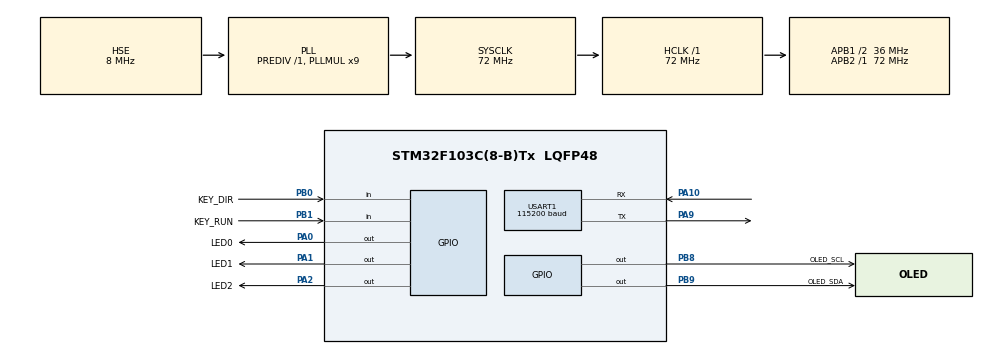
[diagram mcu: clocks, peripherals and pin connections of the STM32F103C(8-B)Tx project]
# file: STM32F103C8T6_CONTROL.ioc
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Mcu.Family=STM32F1
Mcu.Name=STM32F103C(8-B)Tx
Mcu.Package=LQFP48
NVIC.PriorityGroup=NVIC_PRIORITYGROUP_4
PA0.GPIO_Label=LED0
PA0.GPIO_Speed=GPIO_Speed_2MHz
PA0.PinState=GPIO_PIN_RESET
PA0.Signal=GPIO_Output
PA1.GPIO_Label=LED1
PA1.GPIO_Speed=GPIO_Speed_2MHz
PA1.PinState=GPIO_PIN_RESET
PA1.Signal=GPIO_Output
PA2.GPIO_Label=LED2
PA2.GPIO_Speed=GPIO_Speed_2MHz
PA2.PinState=GPIO_PIN_RESET
PA2.Signal=GPIO_Output
PA9.Mode=Asynchronous
PA9.Signal=USART1_TX
PA10.Mode=Asynchronous
PA10.Signal=USART1_RX
PB0.GPIO_Label=KEY_DIR
PB0.GPIO_PuPd=GPIO_PULLUP
PB0.Signal=GPIO_Input
PB1.GPIO_Label=KEY_RUN
PB1.GPIO_PuPd=GPIO_PULLUP
PB1.Signal=GPIO_Input
PB8.GPIO_Label=OLED_SCL
PB8.GPIO_ModeDefaultOutputPP=GPIO_MODE_OUTPUT_OD
PB8.GPIO_PuPd=GPIO_PULLUP
PB8.GPIO_Speed=GPIO_Speed_50MHz
PB8.PinState=GPIO_PIN_SET
PB8.Signal=GPIO_Output
PB9.GPIO_Label=OLED_SDA
PB9.GPIO_ModeDefaultOutputPP=GPIO_MODE_OUTPUT_OD
PB9.GPIO_PuPd=GPIO_PULLUP
PB9.GPIO_Speed=GPIO_Speed_50MHz
PB9.PinState=GPIO_PIN_SET
PB9.Signal=GPIO_Output
ProjectManager.HeapSize=0x200
ProjectManager.StackSize=0x400
ProjectManager.TargetToolchain=STM32CUBEIDE
RCC.AHBFreq_Value=72000000
RCC.APB1CLKDivider=RCC_HCLK_DIV2
RCC.APB1Freq_Value=36000000
RCC.APB1TimFreq_Value=36000000
RCC.APB2Freq_Value=72000000
RCC.APB2TimFreq_Value=72000000
RCC.HCLKFreq_Value=72000000
RCC.LSEState=RCC_LSE_ON
RCC.PLLMUL=RCC_PLL_MUL9
RCC.PLLSourceVirtual=RCC_PLLSOURCE_HSE
RCC.SYSCLKFreq_VALUE=72000000
RCC.SYSCLKSource=RCC_SYSCLKSOURCE_PLLCLK
RCC.USBFreq_Value=72000000
SYS.Debug=Serial Wire
USART1.BaudRate=115200
USART1.VirtualMode=VM_ASYNC
VP_USART1_VS_USART1.Mode=Asynchronous

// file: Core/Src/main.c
/* USER CODE BEGIN Header */
/**
  ******************************************************************************
  * @file    main.c
  * @brief   UART and button controlled LED flow with SSD1306 status display.
  ******************************************************************************
  */
/* USER CODE END Header */

#include "app.h"
#include "gpio.h"
#include "main.h"
#include "usart.h"

void SystemClock_Config(void);

int main(void)
{
  HAL_Init();
  SystemClock_Config();
  MX_GPIO_Init();
  MX_USART1_UART_Init();

  /* USER CODE BEGIN 2 */
  App_Init();
  /* USER CODE END 2 */

  while (1)
  {
    /* USER CODE BEGIN 3 */
    App_Task();
    /* USER CODE END 3 */
  }
}

/**
  * @brief System clock: 8 MHz HSE -> PLL x9 -> 72 MHz.
  */
void SystemClock_Config(void)
{
  RCC_OscInitTypeDef osc = {0};
  RCC_ClkInitTypeDef clock = {0};

  osc.OscillatorType = RCC_OSCILLATORTYPE_HSE;
  osc.HSEState = RCC_HSE_ON;
  osc.HSEPredivValue = RCC_HSE_PREDIV_DIV1;
  osc.HSIState = RCC_HSI_ON;
  osc.PLL.PLLState = RCC_PLL_ON;
  osc.PLL.PLLSource = RCC_PLLSOURCE_HSE;
  osc.PLL.PLLMUL = RCC_PLL_MUL9;
  if (HAL_RCC_OscConfig(&osc) != HAL_OK)
  {
    Error_Handler();
  }

  clock.ClockType = RCC_CLOCKTYPE_HCLK | RCC_CLOCKTYPE_SYSCLK |
                    RCC_CLOCKTYPE_PCLK1 | RCC_CLOCKTYPE_PCLK2;
  clock.SYSCLKSource = RCC_SYSCLKSOURCE_PLLCLK;
  clock.AHBCLKDivider = RCC_SYSCLK_DIV1;
  clock.APB1CLKDivider = RCC_HCLK_DIV2;
  clock.APB2CLKDivider = RCC_HCLK_DIV1;
  if (HAL_RCC_ClockConfig(&clock, FLASH_LATENCY_2) != HAL_OK)
  {
    Error_Handler();
  }
}

void Error_Handler(void)
{
  __disable_irq();
  while (1)
  {
  }
}
